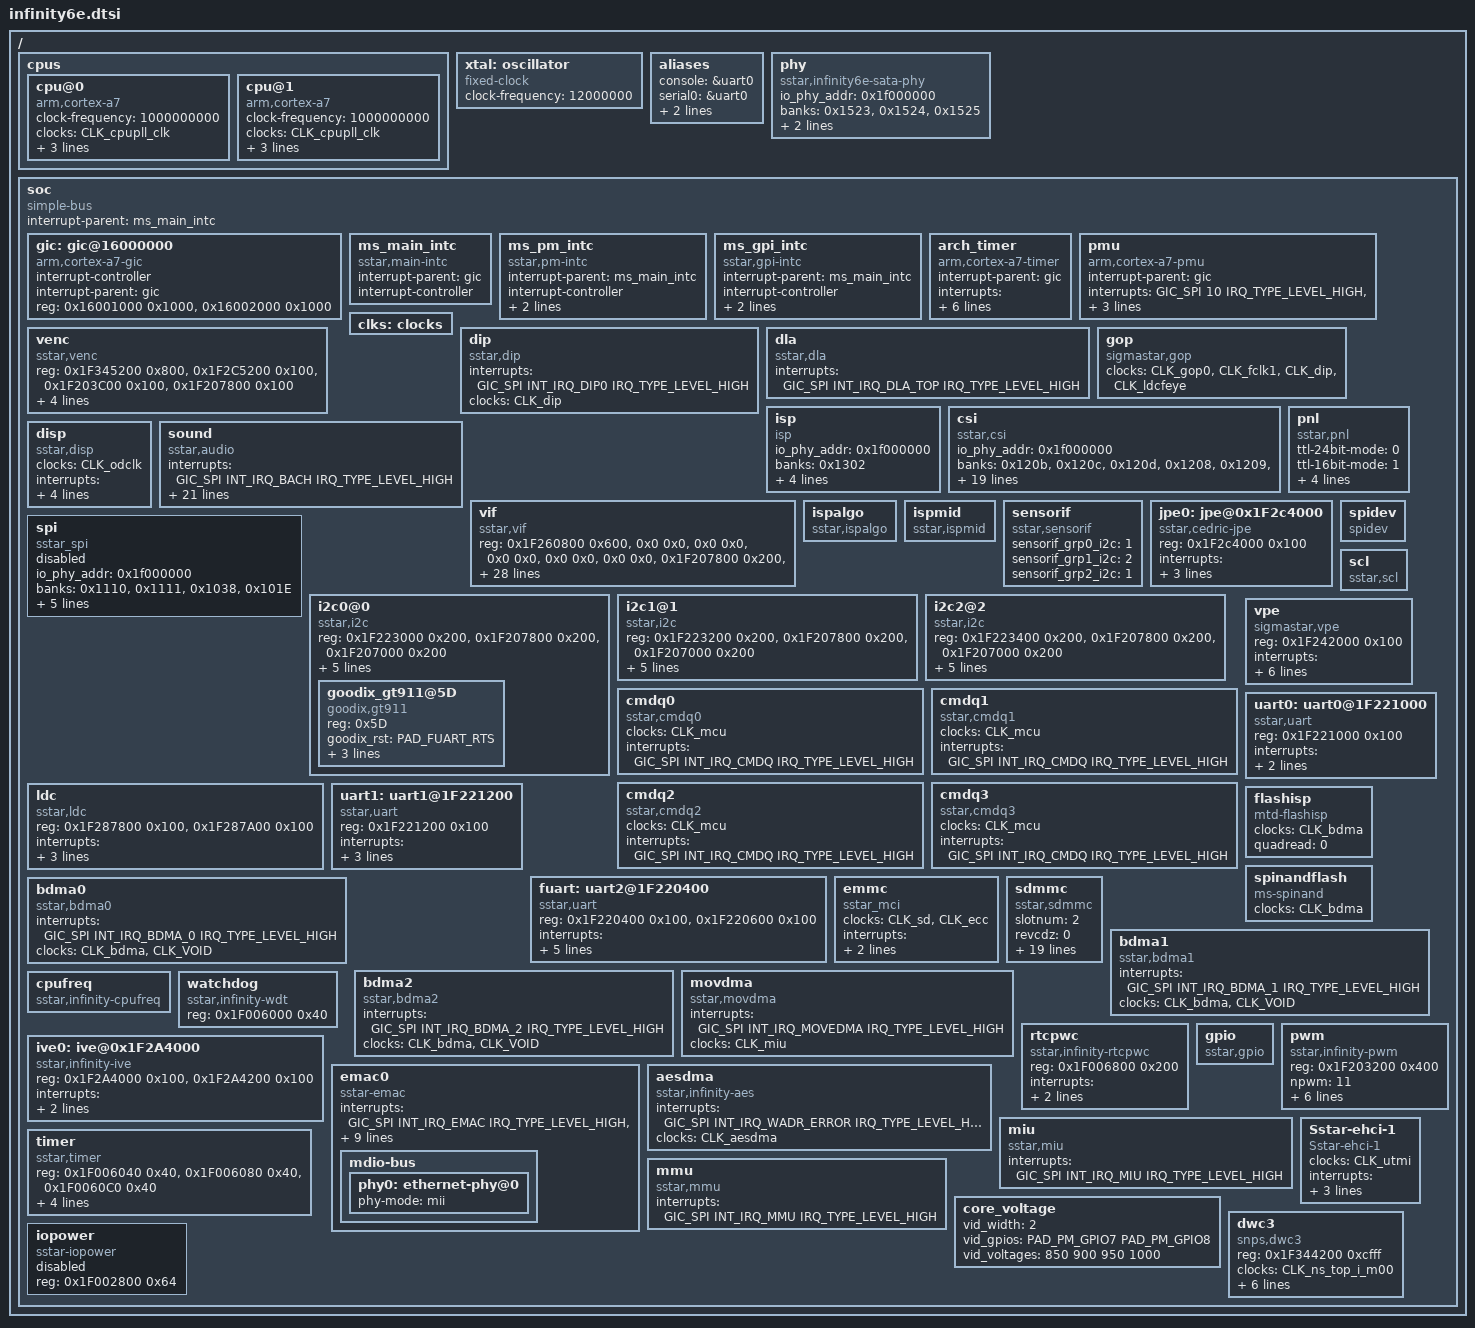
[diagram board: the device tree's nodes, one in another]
/*
* infinity6e.dtsi- Sigmastar
*
* Copyright (c) [2019~2020] SigmaStar Technology.
*
*
* This software is licensed under the terms of the GNU General Public
* License version 2, as published by the Free Software Foundation, and
* may be copied, distributed, and modified under those terms.
*
* This program is distributed in the hope that it will be useful,
* but WITHOUT ANY WARRANTY; without even the implied warranty of
* MERCHANTABILITY or FITNESS FOR A PARTICULAR PURPOSE.  See the
* GNU General Public License version 2 for more details.
*
*/

#include <../../../../drivers/sstar/include/infinity6e/irqs.h>
#include <../../../../drivers/sstar/include/infinity6e/gpio.h>
#include <dt-bindings/interrupt-controller/irq.h>
#include <dt-bindings/interrupt-controller/arm-gic.h>
#include "skeleton.dtsi"


/ {
    cpus {
        #address-cells = <1>;
        #size-cells = <0>;

        cpu@0 {
            device_type = "cpu";
            compatible = "arm,cortex-a7";
            clock-frequency = <1000000000>;
            clocks = <&CLK_cpupll_clk>;
            reg = <0x0>;
            operating-points = <
                /* kHz     uV */
                1200000  850000
                1100000  850000
                1000000  850000
                900000   850000
                800000   850000
                600000   850000
                400000   850000
            >;
        };
#ifndef __DTS_AMP__
        cpu@1 {
            device_type = "cpu";
            compatible = "arm,cortex-a7";
            clock-frequency = <1000000000>;
            clocks = <&CLK_cpupll_clk>;
            reg = <0x1>;
            operating-points = <
                /* kHz     uV */
                1200000  850000
                1100000  850000
                1000000  850000
                900000   850000
                800000   850000
                600000   850000
                400000   850000
            >;
        };
#endif
    };

    xtal: oscillator {
        compatible = "fixed-clock";
        #clock-cells = <0>;
        clock-frequency = <12000000>;
    };

    aliases {
        console = &uart0;
        serial0 = &uart0;
		serial1 = &uart1;
        serial2 = &fuart;
    };

    phy: phy {
        compatible = "sstar,infinity6e-sata-phy";
        io_phy_addr = <0x1f000000>;
        banks = <0x1523>,<0x1524>,<0x1525>;
        reg = <0x1f000000 0x10000>;
        #phy-cells = <0>;
        phy_type = "utmi";
        status = "ok";
    };

    soc {
        compatible = "simple-bus";
        interrupt-parent = <&ms_main_intc>;
        #address-cells = <1>;
        #size-cells = <1>;
        ranges;

        gic: gic@16000000 {
            compatible = "arm,cortex-a7-gic";
            #interrupt-cells = <3>;
            #address-cells = <1>;
            #size-cells = <1>;
            interrupt-controller;
            interrupt-parent = <&gic>;
            reg = <0x16001000 0x1000>,
                  <0x16002000 0x1000>;
        };

        ms_main_intc: ms_main_intc {
            compatible = "sstar,main-intc";
            #interrupt-cells = <3>;
            #address-cells = <1>;
            #size-cells = <1>;
            interrupt-parent=<&gic>;
            interrupt-controller;
        };

        ms_pm_intc: ms_pm_intc {
            compatible = "sstar,pm-intc";
            #interrupt-cells = <1>;
            interrupt-parent=<&ms_main_intc>;
            interrupt-controller;
            interrupts = <GIC_SPI INT_IRQ_PM_SLEEP IRQ_TYPE_LEVEL_HIGH>;
        };

        ms_gpi_intc: ms_gpi_intc {
            compatible = "sstar,gpi-intc";
            #interrupt-cells = <1>;
            interrupt-parent=<&ms_main_intc>;
            interrupt-controller;
            interrupts = <GIC_SPI INT_IRQ_GPI_OUT IRQ_TYPE_LEVEL_HIGH>;
        };

        arch_timer {
            compatible = "arm,cortex-a7-timer", "arm,armv7-timer";
            interrupt-parent=<&gic>;
            interrupts = <GIC_PPI 13 (GIC_CPU_MASK_SIMPLE(2) | IRQ_TYPE_LEVEL_LOW)>,
                         <GIC_PPI 14 (GIC_CPU_MASK_SIMPLE(2) | IRQ_TYPE_LEVEL_LOW)>,
                         <GIC_PPI 11 (GIC_CPU_MASK_SIMPLE(2) | IRQ_TYPE_LEVEL_LOW)>,
                         <GIC_PPI 10 (GIC_CPU_MASK_SIMPLE(2) | IRQ_TYPE_LEVEL_LOW)>;
            clock-frequency = <6000000>;
            always-on;
        };

        pmu {
            compatible = "arm,cortex-a7-pmu";
            interrupt-parent=<&gic>;
            interrupts = <GIC_SPI 10 IRQ_TYPE_LEVEL_HIGH>,
                         <GIC_SPI 16 IRQ_TYPE_LEVEL_HIGH>,
                         <GIC_SPI 22 IRQ_TYPE_LEVEL_HIGH>,
                         <GIC_SPI 28 IRQ_TYPE_LEVEL_HIGH>;
        };

        clks: clocks{
            #address-cells = <1>;
            #size-cells = <1>;
            ranges;
        };

        venc {
            compatible = "sstar,venc";
            reg = <0x1F345200 0x800>, <0x1F2C5200 0x100>, <0x1F203C00 0x100>, <0x1F207800 0x100>;
            reg-names = "vpu-bit", "venc-brige", "hw-uart0", "hw-uart1";
            interrupts = <GIC_SPI INT_IRQ_MHE IRQ_TYPE_LEVEL_HIGH>;
            interrupt-parent = <&ms_main_intc>;
            interrupt-names = "mhe-irq";
            clocks = <&CLK_vhe>, <&CLK_mfe>;
            clock-names = "CKG_venc";
            status = "ok";
        };

        dip {
            compatible = "sstar,dip";
            interrupts=<GIC_SPI INT_IRQ_DIP0 IRQ_TYPE_LEVEL_HIGH>;
            clocks = <&CLK_dip>;
            status = "ok";
        };

        dla {
            compatible = "sstar,dla";
            interrupts=<GIC_SPI INT_IRQ_DLA_TOP IRQ_TYPE_LEVEL_HIGH>;
            status = "ok";
        };

        gop {
            compatible = "sigmastar,gop";
            clocks = <&CLK_gop0>,<&CLK_fclk1>,<&CLK_dip>,<&CLK_ldcfeye>;
            status = "ok";
        };

        isp: isp {
            compatible = "isp";
            io_phy_addr = <0x1f000000>;
            banks = <0x1302>;
            interrupts = <GIC_SPI INT_IRQ_ISP IRQ_TYPE_LEVEL_HIGH>;
            clocks = <&CLK_isp>;
            status = "ok";
            clock-frequency-index = <0>;
        };

        csi: csi {
            compatible = "sstar,csi";
            io_phy_addr = <0x1f000000>;
            banks = <0x120b>,<0x120c>,<0x120d>,<0x1208>,<0x1209>,<0x120a>,<0x1202>,<0x1203>,<0x1204>,<0x1038>,<0x120e>;
            interrupts=  <GIC_SPI INT_IRQ_MIPI_CSI2 IRQ_TYPE_LEVEL_HIGH>;
            clocks = <&CLK_csi_mac_lptx_top_i_m00>,<&CLK_csi_mac_top_i_m00>,<&CLK_ns_top_i_m00>,<&CLK_csi_mac_lptx_top_i_m1>,<&CLK_csi_mac_top_i_m1>,<&CLK_ns_top_i_m1>,<&CLK_csi_mac_lptx_top_i_m01>,<&CLK_csi_mac_top_i_m01>,<&CLK_ns_top_i_m01>;
            status = "ok";
            /* Config max lane number */
            csi_sr0_lane_num = <4>;
            csi_sr1_lane_num = <4>;
            csi_sr2_lane_num = <2>;
            /* Config lane selection */
            csi_sr0_lane_select = <2 4 3 1 0>;
            csi_sr1_lane_select = <2 0 1 3 4>;
            csi_sr2_lane_select = <0 0 0>;
            /* Config lane P/N swap */
            csi_sr0_lane_pn_swap = <1 1 1 1 1>;
            csi_sr1_lane_pn_swap = <0 0 0 0 0>;
            csi_sr2_lane_pn_swap = <0 0 0>;
        };
		pnl: pnl {
            compatible = "sstar,pnl";
            status = "ok";
            ttl-24bit-mode = <0>; //only 1 mode
            ttl-16bit-mode = <1>; //1~4 mode
            jtag-mode = <1>;
            clocks = <&CLK_odclk>;
            clock-names = "CLK_odclk";
            interrupts = <GIC_SPI INT_IRQ_SC2_TOP_INT IRQ_TYPE_LEVEL_HIGH>;
            //Reg = <0x1F224000 0x200>;
        };
        disp: disp {
            compatible = "sstar,disp";
            status = "ok";
            clocks = <&CLK_odclk>;
            clock-names = "CLK_odclk";
            //Reg = <0x1F224000 0x200>;
            interrupts = <GIC_SPI INT_IRQ_SC_TOP IRQ_TYPE_LEVEL_HIGH>, <GIC_SPI INT_IRQ_SC1_TOP_INT IRQ_TYPE_LEVEL_HIGH>, <GIC_SPI INT_IRQ_SC2_TOP_INT IRQ_TYPE_LEVEL_HIGH>, <GIC_SPI INT_IRQ_CMDQ IRQ_TYPE_LEVEL_HIGH>;
        };
        sound {
            compatible = "sstar,audio";
//            reg = <0x1F000000 0x1000000>;
            interrupts=<GIC_SPI INT_IRQ_BACH IRQ_TYPE_LEVEL_HIGH>;
            playback-volume-level=<64>;    //0~94
            capture-volume-level=<64>;
           // micin-pregain-level=<1>;    //0~3
            micin-pregain-level=<0>;    //0~3
            micin-gain-level=<3>;    //0~7
            linein-gain-level=<2>;  //0~7
            amp-gpio = <PAD_PM_GPIO1  1>;
            clocks = <&CLK_bach>;
           // playback-dma-buffer=<98304>; //512(ms)*48(kHz)*2(ch)*2(16bits)
           // capture-dma-buffer=<122880>; //640(ms)*48(kHz)*2(ch)*2(16bits)
            digmic-padmux = <6>; //1~6
            i2s-trx-shared-padmux = <1>; //for 4-wired mode panmux
            i2s-tx-padmux = <0>; //6-wired mode
            i2s-rx-padmux = <0>; //6-wired mode
            i2smck-padmux = <1>; //
            i2smod-padmux = <0>; //0:i2s tdm, 1:i2s normal
            keep-i2s-clk = <0>;
            //I2S RX TDM
            i2s-rx-tdm-ws-pgm = <0>; // 0: OFF  1: ON
            i2s-rx-tdm-ws-width = <0>; // value: 0~31 (width = value + 1)
            i2s-rx-tdm-ch-swap = <0 0>; // 0: OFF  1: ON

            //I2S TX TDM
            i2s-tx-tdm-ws-pgm = <0>; // 0: OFF  1: ON
            i2s-tx-tdm-ws-width = <0>; // value: 0~31 (width = value + 1)
            i2s-tx-tdm-ch-swap = <0 0>; // 0: OFF  1: ON
            i2s-tx-tdm-active-slot = <0x03>; // value: 0x00 ~ 0xFF (bit0->slot0, bit1->slot1, ... )

            status = "ok";
        };
        vif: vif {
            compatible = "sstar,vif";
            status = "ok";
            reg = <0x1F260800 0x600>, <0x0 0x0>, <0x0 0x0>, <0x0 0x0>, <0x0 0x0>, <0x0 0x0>, <0x1F207800 0x200>, <0x1F226600 0x200>, <0x1F207000 0x200>, <0x1F000000 0x400000>, <0x1F203C00 0x200>;
            clocks = <&CLK_sr00_mclk>,<&CLK_sr1_mclk>,<&CLK_sr01_mclk>;
            interrupts = <GIC_SPI INT_IRQ_VIF IRQ_TYPE_LEVEL_HIGH>;
            /* Config sensor 0 pad mux */
            vif_sr0_par_mode = <2>;
            vif_sr0_mipi_mode = <1>;
            vif_sr0_bt656_mode = <1>;
            vif_sr0_mclk_mode = <0>;
            //vif_sr0_rst_mode  = <0>;
            //vif_sr0_pdn_mode  = <0>;
            vif_sr0_parallel_rst_mode  = <0>;
            vif_sr0_parallel_pdn_mode  = <0>;
            vif_sr0_mipi_rst_mode  = <0>;
            vif_sr0_mipi_pdn_mode  = <1>;
            vif_sr0_mipi_ctrl_mode = <1>;
            //vif_sr0_hvsync_mode  = <0>; /* Not used in I6E */
            //vif_sr0_pck_mode  = <0>; /* Not used in I6E */
            /* Config sensor 1 pad mux */
            vif_sr1_par_mode = <0>;
            vif_sr1_mipi_mode = <1>;
            vif_sr1_bt656_mode = <0>;
            vif_sr1_mipi_ctrl_mode = <1>;
            vif_sr1_mclk_mode = <0>;
            vif_sr1_rst_mode  = <0>;
            /* Config sensor 2 pad mux */
            vif_sr2_mipi_mode = <0>; /* MIPI sensor only */
            vif_sr2_mipi_ctrl_mode = <0>;
            vif_sr2_mclk_mode = <0>;
            vif_sr2_rst_mode  = <0>;
            /* Config mclk 37.125MHz supported */
            vif_sr0_mclk_37p125 = <1>;
            vif_sr1_mclk_37p125 = <1>;
            vif_sr2_mclk_37p125 = <1>;
        };

        ispalgo: ispalgo {
            compatible = "sstar,ispalgo";
            status = "ok";
        };

        ispmid: ispmid {
            compatible = "sstar,ispmid";
            status = "ok";
        };

        sensorif: sensorif {
            compatible = "sstar,sensorif";
            status = "ok";
            sensorif_grp0_i2c = <1>;
            sensorif_grp1_i2c = <2>;
            sensorif_grp2_i2c = <1>; //ToDo?
        };

        jpe0: jpe@0x1F2c4000 {
            compatible = "sstar,cedric-jpe";
            reg = <0x1F2c4000 0x100>;
            interrupts = <GIC_SPI INT_IRQ_JPE IRQ_TYPE_LEVEL_HIGH>;
            clocks = <&CLK_jpe>;
            clock-names = "CKG_jpe";
            clk-select = <0>; // 0: 288MHz  1: 216MHz  2: 54MHz  3: 27MHz
            status = "ok";
        };

		spi: spi {
            compatible = "sstar_spi";
            io_phy_addr = <0x1f000000>;
            banks = <0x1110>,<0x1111>,<0x1038>,<0x101E>;
            interrupts = <GIC_SPI INT_IRQ_MSPI_0 IRQ_TYPE_LEVEL_HIGH>,<GIC_SPI INT_IRQ_MSPI_1 IRQ_TYPE_LEVEL_HIGH>;
            spi0_mode = <1>;
            spi1_mode = <3>;
            status = "disabled";
        };

        spidev: spidev {
            compatible = "spidev";
        };
		
        i2c0@0{
            compatible = "sstar,i2c";
            reg = <0x1F223000 0x200>,<0x1F207800 0x200>,<0x1F207000 0x200>;
                #address-cells = <1>;
                #size-cells = <0>;
            clocks = <&CLK_miic0>;
            i2c-group = <0>;
            status = "ok";
            /*
             * padmux: 1 -> PAD_I2C0_SCL, PAD_I2C0_SDA
             *         2 -> PAD_ETH_LED0, PAD_ETH_LED1
             *         3 -> PAD_GPIO6, PAD_GPIO7
             *         4 -> PAD_SR1_IO00, PAD_SR1_IO01
             *         5 -> PAD_GPIO12, PAD_GPIO13
            */
            i2c-padmux = <3>;
            interrupts=<GIC_SPI INT_IRQ_MIIC_0 IRQ_TYPE_LEVEL_HIGH>;
            goodix_gt911@5D{ //EVB i2c-padmux=2 SSD201_SZ_DEMO_BOARD i2c-padmux=1
                compatible = "goodix,gt911";
                reg = <0x5D>;
                goodix_rst = <PAD_FUART_RTS>; //SSD201_SZ_DEMO_BOARD PAD_GPIO1  EVB PAD_GPIO0
                goodix_int = <PAD_GPIO5>; //SSD201_SZ_DEMO_BOARD PAD_GPIO13  EVB PAD_GPIO1
                interrupts-extended = <&ms_gpi_intc INT_GPI_FIQ_PAD_GPIO5>;
                interrupt-names = "goodix_int";
            };
        };

        i2c1@1{
            compatible = "sstar,i2c";
            reg = <0x1F223200 0x200>,<0x1F207800 0x200>,<0x1F207000 0x200>;
                #address-cells = <1>;
                #size-cells = <0>;
            clocks = <&CLK_miic1>;
            i2c-group = <1>;
            /*
             * padmux: 1 -> PAD_SR0_IO18, PAD_SR0_IO19
             *         2 -> PAD_GPIO0, PAD_GPIO1
             *         3 -> PAD_SR0_IO18, PAD_SR0_IO19
            */
            i2c-padmux = <1>;
            interrupts=<GIC_SPI INT_IRQ_MIIC_1 IRQ_TYPE_LEVEL_HIGH>;
            status = "ok";
//            24c512@54 {
//                compatible = "sstar,24c512";
//                reg = <0x54>;
//            };
        };

        i2c2@2{
            compatible = "sstar,i2c";
            reg = <0x1F223400 0x200>,<0x1F207800 0x200>,<0x1F207000 0x200>;
                #address-cells = <1>;
                #size-cells = <0>;
            clocks = <&CLK_miic2>;
            i2c-group = <2>;
            /*
             * padmux: 1 -> PAD_SR1_IO18, PAD_SR1_IO19
             *         2 -> PAD_PWM0, PAD_PWM1
             *         3 -> PAD_ETH_LED0, PAD_ETH_LED1
             *         4 -> PAD_PM_I2CM_SCL, PAD_PM_I2CM_SDA
             *         5 -> PAD_PM_GPIO0, PAD_PM_GPIO1
            */
            i2c-padmux = <1>;
            interrupts=<GIC_SPI INT_IRQ_MIIC_2 IRQ_TYPE_LEVEL_HIGH>;
            status = "ok";
        };

        cmdq0 {
            compatible = "sstar,cmdq0";
            clocks = <&CLK_mcu>; //for timeout tick
            interrupts=<GIC_SPI INT_IRQ_CMDQ IRQ_TYPE_LEVEL_HIGH>;
            status = "ok";
        };

        cmdq1 {
            compatible = "sstar,cmdq1";
            clocks = <&CLK_mcu>; //for timeout tick
            interrupts=<GIC_SPI INT_IRQ_CMDQ IRQ_TYPE_LEVEL_HIGH>;
            status = "ok";
        };

        cmdq2 {
            compatible = "sstar,cmdq2";
            clocks = <&CLK_mcu>; //for timeout tick
            interrupts=<GIC_SPI INT_IRQ_CMDQ IRQ_TYPE_LEVEL_HIGH>;
            status = "ok";
        };

        cmdq3 {
            compatible = "sstar,cmdq3";
            clocks = <&CLK_mcu>; //for timeout tick
            interrupts=<GIC_SPI INT_IRQ_CMDQ IRQ_TYPE_LEVEL_HIGH>;
            status = "ok";
        };

        ldc: ldc {
            compatible = "sstar,ldc";
            reg = <0x1F287800 0x100>, <0x1F287A00 0x100>;
            interrupts=<GIC_SPI INT_IRQ_LDC_FEYE IRQ_TYPE_LEVEL_HIGH>;
            clocks = <&CLK_ldcfeye>;
            clock-names = "CLK_ldcfeye";
            clk-select = <1>; // 0: 480MHz  1: 432MHz  2: 384MHz  3: 320MHz  4: 288MHz  5: 216MHz  6: 86MHz
            status = "ok";
        };

        scl: scl {
            compatible = "sstar,scl";
            status = "ok";
        };

        vpe: vpe {
            compatible = "sigmastar,vpe";
            reg = <0x1F242000 0x100>;
            interrupts = <GIC_SPI INT_IRQ_SC_TOP IRQ_TYPE_LEVEL_HIGH>, <GIC_SPI INT_IRQ_SC1_TOP_INT IRQ_TYPE_LEVEL_HIGH>, <GIC_SPI INT_IRQ_SC2_TOP_INT IRQ_TYPE_LEVEL_HIGH>, <GIC_SPI INT_IRQ_CMDQ IRQ_TYPE_LEVEL_HIGH>;
            clocks = <&CLK_fclk1>,<&CLK_odclk>;
            clock-names = "CLK_fclk1","CLK_fclk2","CLK_odclk";
            clk-select = <2>;
            status = "ok";
        };

        uart0: uart0@1F221000 {
            compatible = "sstar,uart";
            reg = <0x1F221000 0x100>;
            interrupts= <GIC_SPI INT_IRQ_UART_0 IRQ_TYPE_LEVEL_HIGH>;
            status = "ok";
            clocks = <&CLK_uart0>;
        };		
		uart1: uart1@1F221200 {
            compatible = "sstar,uart";
            reg = <0x1F221200 0x100>;
            interrupts = <GIC_SPI INT_IRQ_UART_1 IRQ_TYPE_LEVEL_HIGH>;
            clocks = <&CLK_uart1>;
            pad = <PAD_GPIO0>;
            //pad = <PAD_FUART_RTS>;
            //pad = <PAD_GPIO6>;
            status = "ok";
        };
        fuart: uart2@1F220400 {
            compatible = "sstar,uart";
            reg = <0x1F220400 0x100>, <0x1F220600 0x100>;
            interrupts = <GIC_SPI INT_IRQ_FUART IRQ_TYPE_LEVEL_HIGH>, <GIC_SPI INT_IRQ_URDMA IRQ_TYPE_LEVEL_HIGH>;
            clocks = <&CLK_fuart>;
            dma = <1>;
            pad = <PAD_PM_GPIO2>;
            //pad = <PAD_FUART_RX>;
            //pad = <PAD_FUART_TX>;
            //pad = <PAD_GPIO4>;
            status = "ok";
        };		
		
        flashisp {
            compatible = "mtd-flashisp";
            clocks = <&CLK_bdma>;
            quadread = <0>;
            status = "ok";
        };

        spinandflash {
            compatible = "ms-spinand";
            clocks =<&CLK_bdma>;
            status = "ok";
        };

        emmc {
            compatible = "sstar_mci";
            clocks =<&CLK_sd>, <&CLK_ecc>;
            interrupts =  <GIC_SPI INT_IRQ_SD IRQ_TYPE_LEVEL_HIGH>;
            bus-width = <8>;
            status = "ok";
        };

        sdmmc {
            compatible = "sstar,sdmmc";

            slotnum = <2>;
            revcdz = <0>;

            slot-ip-orders = <0>,<1>,<2>;
            slot-pad-orders = <0>,<1>,<2>;
            slot-max-clks = <48000000>,<48000000>,<48000000>;
            slot-intcdzs = <1>,<1>,<0>;
            slot-fakecdzs = <0>,<0>,<0>;
            slot-cdzs-gpios = <PAD_SD0_CDZ>,<PAD_SD1_CDZ>,<PAD_UNKNOWN>;
            slot-pwr-gpios = <PAD_SD0_GPIO0>,<PAD_SD1_GPIO0>,<PAD_UNKNOWN>;
            slot-pwr-off-delay = <30>,<30>,<30>;
            slot-sdio-use = <0>,<0>,<0>;

            interrupts-extended = <&ms_main_intc GIC_SPI INT_IRQ_SD IRQ_TYPE_LEVEL_HIGH>,//was INT_IRQ_SDIO
                                  <&ms_main_intc GIC_SPI INT_IRQ_SDIO IRQ_TYPE_LEVEL_HIGH>,
                                  <&ms_main_intc GIC_SPI INT_FIQ_SD_CDZ_0 IRQ_TYPE_LEVEL_HIGH>,
                                  <&ms_main_intc GIC_SPI INT_FIQ_SD_CDZ_1 IRQ_TYPE_LEVEL_HIGH>;
            interrupt-names = "mie0_irq", "mie1_irq", "cdz_slot0_irq", "cdz_slot1_irq";
            clocks = <&CLK_sd>,<&CLK_sdio>,<&CLK_VOID>,
                     <&CLK_sd>,<&CLK_sdio>,<&CLK_VOID>,
                     <&CLK_sd>,<&CLK_sdio>,<&CLK_VOID>;
            status = "ok";
        };

        bdma0 {
            compatible = "sstar,bdma0";
            interrupts=<GIC_SPI INT_IRQ_BDMA_0 IRQ_TYPE_LEVEL_HIGH>;
            clocks = <&CLK_bdma>,<&CLK_VOID>;
            status = "ok";
        };

        bdma1 {
            compatible = "sstar,bdma1";
            interrupts=<GIC_SPI INT_IRQ_BDMA_1 IRQ_TYPE_LEVEL_HIGH>;
            clocks = <&CLK_bdma>,<&CLK_VOID>;
            status = "ok";
        };

        bdma2 {
            compatible = "sstar,bdma2";
            interrupts=<GIC_SPI INT_IRQ_BDMA_2 IRQ_TYPE_LEVEL_HIGH>;
            clocks = <&CLK_bdma>,<&CLK_VOID>;
            status = "ok";
        };
/*
        bdma3 {
            compatible = "sstar,bdma3";
            interrupts=<GIC_SPI INT_IRQ_BDMA_3 IRQ_TYPE_LEVEL_HIGH>;
            clocks = <&CLK_bdma>,<&CLK_VOID>;
            status = "ok";
        };
*/
        movdma {
            compatible = "sstar,movdma";
            interrupts=<GIC_SPI INT_IRQ_MOVEDMA IRQ_TYPE_LEVEL_HIGH>;
            clocks = <&CLK_miu>;
            status = "ok";
        };

        cpufreq {
            compatible = "sstar,infinity-cpufreq";
            status = "ok";
        };

        watchdog: watchdog {
            compatible = "sstar,infinity-wdt";
            reg = <0x1F006000 0x40>;
            status = "ok";
        };

        rtcpwc {
            compatible = "sstar,infinity-rtcpwc";
            reg = <0x1F006800 0x200>;
            interrupts=<GIC_SPI INT_IRQ_RTC IRQ_TYPE_LEVEL_HIGH>; //need to check
            clocks = <&CLK_rtc>;
            status = "ok";
        };

        ive0: ive@0x1F2A4000 {
            compatible = "sstar,infinity-ive";
            reg = <0x1F2A4000 0x100>,<0x1F2A4200 0x100>;
            interrupts = <GIC_SPI INT_IRQ_IVE IRQ_TYPE_LEVEL_HIGH>;
            clocks = <&CLK_ive>;
            status = "ok";
        };

        emac0: emac0 {
            compatible = "sstar-emac";
            interrupts = <GIC_SPI INT_IRQ_EMAC IRQ_TYPE_LEVEL_HIGH>, <GIC_SPI INT_FIQ_LAN_ESD IRQ_TYPE_LEVEL_HIGH>;
            clocks = <&CLK_emac_ahb>,<&CLK_emac_tx>,<&CLK_emac_rx>,<&CLK_emac_tx_ref>,<&CLK_emac_rx_ref>;
            reg = <0x1F2A2000 0x800>, <0x1F343C00 0x600>, <0x1F2A2800 0x600>;
            //reg = <0x1F2A2000 0x800>, <0x1F343C00 0x600>, <0x00000000 0x000>;	// for RMII
            pad = <0x1F2079B8 0x0001 0x0001>;	// for RMII
            pad_led = <0x1F20798C 0x0077 0x0021>;
            phy-handle = <&phy0>;
            status = "ok";
            mdio-bus {
                phy0: ethernet-phy@0 {
                    phy-mode = "mii";
                };
            };
        };

        gpio:gpio{
            compatible = "sstar,gpio";
        };

        pwm {
            compatible = "sstar,infinity-pwm";
            //reg = <0x1F003400 0x200>; /* PM-PWM(BK:x1A) */
            //npwm = <1>;
            reg = <0x1F203200 0x400>; /* NonPM-PWM(BK:x1019 and x101A) */
            npwm = <11>;
            pm_group_base = <0x1F003400>;
            clocks = <&CLK_xtali_12m>;
            interrupts=<GIC_SPI INT_IRQ_BOOT_TOP IRQ_TYPE_LEVEL_HIGH>; //Only4i6e; Others, pls check hold0 int supporting.
            pad-ctrl = <PAD_GPIO8 PAD_GPIO9 PAD_GPIO10 PAD_GPIO11 PAD_GPIO12 PAD_GPIO13 PAD_GPIO14 PAD_GPIO15 PAD_UNKNOWN PAD_PM_GPIO9 PAD_PM_GPIO1>;
            status = "ok";
        };

        aesdma {
            compatible = "sstar,infinity-aes";
            interrupts=<GIC_SPI INT_IRQ_WADR_ERROR IRQ_TYPE_LEVEL_HIGH>;
            clocks = <&CLK_aesdma>;
            status = "ok";
        };

        miu {
            compatible = "sstar,miu";
            interrupts=<GIC_SPI INT_IRQ_MIU IRQ_TYPE_LEVEL_HIGH>;
            status = "ok";
        };

        mmu {
            compatible = "sstar,mmu";
            interrupts=<GIC_SPI INT_IRQ_MMU IRQ_TYPE_LEVEL_HIGH>;
            status = "ok";
        };

        timer {
            compatible = "sstar,timer";
            reg = <0x1F006040 0x40>, <0x1F006080 0x40>, <0x1F0060C0 0x40>;
            interrupts = <GIC_SPI INT_FIQ_TIMER_0 IRQ_TYPE_LEVEL_HIGH>, <GIC_SPI INT_FIQ_TIMER_1 IRQ_TYPE_LEVEL_HIGH>, <GIC_SPI INT_FIQ_TIMER_2 IRQ_TYPE_LEVEL_HIGH>;
            status = "ok";
        };

        core_voltage {
            vid_width = <2>;
            vid_gpios = <PAD_PM_GPIO7 PAD_PM_GPIO8>;
            vid_voltages = <850 900 950 1000>;  //2b'00 2b'01 2b'10 2b'11
        };

        Sstar-ehci-1 {
            compatible = "Sstar-ehci-1";
            clocks = <&CLK_utmi>;
            interrupts = <GIC_SPI INT_IRQ_UHC IRQ_TYPE_LEVEL_HIGH>;
            dpdm_swap=<0>;
            power-enable-pad = <PAD_GPIO8>;
            status = "ok";
        };

        dwc3: dwc3 {
            compatible = "snps,dwc3";
            reg = <0x1F344200 0xcfff>;
            clocks = <&CLK_ns_top_i_m00>;
            clock-names = "ss_clk";
            maximum-speed = "super-speed";
            interrupts = <GIC_SPI INT_IRQ_USB3_GP2TOP IRQ_TYPE_LEVEL_HIGH>;
            interrupt-names = "dwc_usb3";
            phy_type = "utmi_wide";
            phys = <&phy>, <&phy>;
            phy-names = "usb2-phy", "usb3-phy";
            snps,incr-burst-type-adjustment = <1>, <4>, <8>, <16>;
       };

       iopower {
            compatible = "sstar-iopower";
            reg = <0x1F002800 0x64>;
            status = "disabled";
        };


    };
};

&clks {
    #include <../../../../drivers/sstar/include/infinity6e/reg_clks.h>
    #include "infinity6e-clks.dtsi"
};
